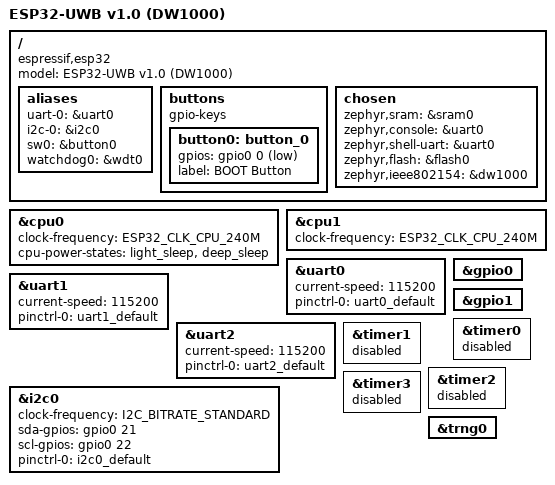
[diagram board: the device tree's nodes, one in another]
/*
 * Copyright (c) 2024 Espressif Shanghai
 *
 * SPDX-License-Identifier: Apache-2.0
 */
/dts-v1/;

#include <espressif/esp32/esp32_wrover_e_n16r8.dtsi>
#include "esp32_uwb-pinctrl.dtsi"
#include <espressif/partitions_amp_default.dtsi>

/ {
	model = "ESP32-UWB v1.0 (DW1000)";
	compatible = "espressif,esp32";

	aliases {
		uart-0 = &uart0;
		i2c-0 = &i2c0;
		sw0 = &button0;
		watchdog0 = &wdt0;
	};

	buttons {
		compatible = "gpio-keys";
		button0: button_0 {
			gpios = <&gpio0 0 (GPIO_PULL_UP | GPIO_ACTIVE_LOW)>;
			label = "BOOT Button";
		};
	};

	chosen {
		zephyr,sram = &sram0;
		zephyr,console = &uart0;
		zephyr,shell-uart = &uart0;
		zephyr,flash = &flash0;
		zephyr,ieee802154 = &dw1000;
	};

};

&cpu0 {
	clock-frequency = <ESP32_CLK_CPU_240M>;
	cpu-power-states = <&light_sleep &deep_sleep>;
};

&cpu1 {
	clock-frequency = <ESP32_CLK_CPU_240M>;
};

&uart0 {
	status = "okay";
	current-speed = <115200>;
	pinctrl-0 = <&uart0_default>;
	pinctrl-names = "default";
};

&uart1 {
	current-speed = <115200>;
	pinctrl-0 = <&uart1_default>;
	pinctrl-names = "default";
};

&uart2 {
	current-speed = <115200>;
	pinctrl-0 = <&uart2_default>;
	pinctrl-names = "default";
};

&gpio0 {
	status = "okay";
};

&gpio1 {
	status = "okay";
};

&i2c0 {
	status = "okay";
	clock-frequency = <I2C_BITRATE_STANDARD>;
	sda-gpios = <&gpio0 21 GPIO_OPEN_DRAIN>;
	scl-gpios = <&gpio0 22 GPIO_OPEN_DRAIN>;
	pinctrl-0 = <&i2c0_default>;
	pinctrl-names = "default";
};

&timer0 {
	status = "disabled";
};

&timer1 {
	status = "disabled";
};

&timer2 {
	status = "disabled";
};

&timer3 {
	status = "disabled";
};

&trng0 {
	status = "okay";
};
